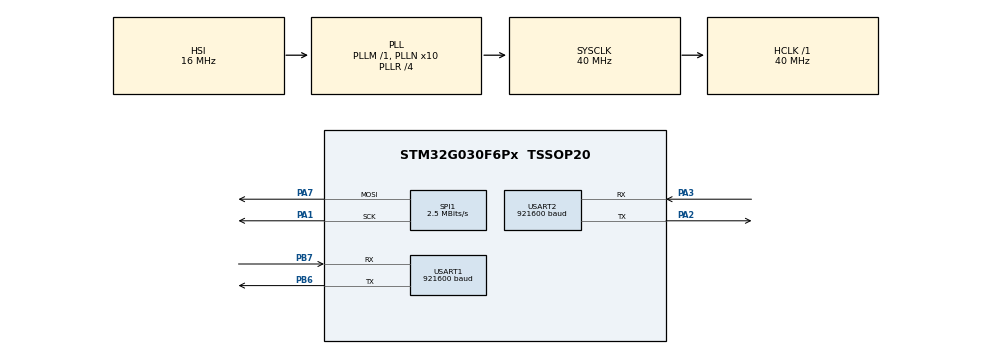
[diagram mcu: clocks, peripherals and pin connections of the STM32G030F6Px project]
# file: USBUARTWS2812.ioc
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Dma.Request0=SPI1_TX
Dma.Request1=USART1_RX
Dma.Request2=USART2_TX
Dma.SPI1_TX.0.Direction=DMA_MEMORY_TO_PERIPH
Dma.SPI1_TX.0.EventEnable=DISABLE
Dma.SPI1_TX.0.Instance=DMA1_Channel1
Dma.SPI1_TX.0.MemDataAlignment=DMA_MDATAALIGN_BYTE
Dma.SPI1_TX.0.MemInc=DMA_MINC_ENABLE
Dma.SPI1_TX.0.Mode=DMA_NORMAL
Dma.SPI1_TX.0.PeriphDataAlignment=DMA_PDATAALIGN_BYTE
Dma.SPI1_TX.0.PeriphInc=DMA_PINC_DISABLE
Dma.SPI1_TX.0.Polarity=HAL_DMAMUX_REQ_GEN_RISING
Dma.SPI1_TX.0.Priority=DMA_PRIORITY_LOW
Dma.SPI1_TX.0.RequestNumber=1
Dma.SPI1_TX.0.SignalID=NONE
Dma.SPI1_TX.0.SyncEnable=DISABLE
Dma.SPI1_TX.0.SyncPolarity=HAL_DMAMUX_SYNC_NO_EVENT
Dma.SPI1_TX.0.SyncRequestNumber=1
Dma.SPI1_TX.0.SyncSignalID=NONE
Dma.USART1_RX.1.Direction=DMA_PERIPH_TO_MEMORY
Dma.USART1_RX.1.EventEnable=DISABLE
Dma.USART1_RX.1.Instance=DMA1_Channel2
Dma.USART1_RX.1.MemDataAlignment=DMA_MDATAALIGN_BYTE
Dma.USART1_RX.1.MemInc=DMA_MINC_ENABLE
Dma.USART1_RX.1.Mode=DMA_NORMAL
Dma.USART1_RX.1.PeriphDataAlignment=DMA_PDATAALIGN_BYTE
Dma.USART1_RX.1.PeriphInc=DMA_PINC_DISABLE
Dma.USART1_RX.1.Polarity=HAL_DMAMUX_REQ_GEN_RISING
Dma.USART1_RX.1.Priority=DMA_PRIORITY_LOW
Dma.USART1_RX.1.RequestNumber=1
Dma.USART1_RX.1.SignalID=NONE
Dma.USART1_RX.1.SyncEnable=DISABLE
Dma.USART1_RX.1.SyncPolarity=HAL_DMAMUX_SYNC_NO_EVENT
Dma.USART1_RX.1.SyncRequestNumber=1
Dma.USART1_RX.1.SyncSignalID=NONE
Dma.USART2_TX.2.Direction=DMA_MEMORY_TO_PERIPH
Dma.USART2_TX.2.EventEnable=DISABLE
Dma.USART2_TX.2.Instance=DMA1_Channel3
Dma.USART2_TX.2.MemDataAlignment=DMA_MDATAALIGN_BYTE
Dma.USART2_TX.2.MemInc=DMA_MINC_ENABLE
Dma.USART2_TX.2.Mode=DMA_NORMAL
Dma.USART2_TX.2.PeriphDataAlignment=DMA_PDATAALIGN_BYTE
Dma.USART2_TX.2.PeriphInc=DMA_PINC_DISABLE
Dma.USART2_TX.2.Polarity=HAL_DMAMUX_REQ_GEN_RISING
Dma.USART2_TX.2.Priority=DMA_PRIORITY_LOW
Dma.USART2_TX.2.RequestNumber=1
Dma.USART2_TX.2.SignalID=NONE
Dma.USART2_TX.2.SyncEnable=DISABLE
Dma.USART2_TX.2.SyncPolarity=HAL_DMAMUX_SYNC_NO_EVENT
Dma.USART2_TX.2.SyncRequestNumber=1
Dma.USART2_TX.2.SyncSignalID=NONE
Mcu.Family=STM32G0
Mcu.Name=STM32G030F6Px
Mcu.Package=TSSOP20
NVIC.DMA1_Channel1_IRQn=true\:0\:0\:false\:false\:true\:false\:true\:true
NVIC.DMA1_Channel2_3_IRQn=true\:0\:0\:false\:false\:true\:false\:true\:true
NVIC.TIM3_IRQn=true\:0\:0\:false\:false\:true\:true\:true\:true
NVIC.USART1_IRQn=true\:0\:0\:false\:false\:true\:true\:true\:true
NVIC.USART2_IRQn=true\:0\:0\:false\:false\:true\:true\:true\:true
PA1.Mode=TX_Only_Simplex_Unidirect_Master
PA1.Signal=SPI1_SCK
PA13.Mode=Serial_Wire
PA13.Signal=SYS_SWDIO
PA14-BOOT0.Mode=Serial_Wire
PA14-BOOT0.Signal=SYS_SWCLK
PA14-BOOT0__PA15.StandardMode=true
PA2.Mode=Asynchronous
PA2.Signal=USART2_TX
PA3.Mode=Asynchronous
PA3.Signal=USART2_RX
PA7.GPIO_Speed=GPIO_SPEED_FREQ_VERY_HIGH
PA7.Mode=TX_Only_Simplex_Unidirect_Master
PA7.Signal=SPI1_MOSI
PB0__PB1__PB2__PA8.StandardMode=true
PB3__PB4__PB5__PB6.StandardMode=true
PB6.Mode=Asynchronous
PB6.Signal=USART1_TX
PB7.Mode=Asynchronous
PB7.Signal=USART1_RX
PB7__PB8.StandardMode=true
PC14-OSC32_IN\ (PC14)__PB9.StandardMode=true
ProjectManager.HeapSize=0x200
ProjectManager.StackSize=0x400
ProjectManager.TargetToolchain=Makefile
RCC.ADCFreq_Value=40000000
RCC.AHBFreq_Value=40000000
RCC.CortexFreq_Value=40000000
RCC.EXTERNAL_CLOCK_VALUE=12288000
RCC.HCLKFreq_Value=40000000
RCC.HSE_VALUE=8000000
RCC.HSI_VALUE=16000000
RCC.LSE_VALUE=32768
RCC.PLLN=10
RCC.PLLR=RCC_PLLR_DIV4
RCC.SYSCLKFreq_VALUE=40000000
RCC.SYSCLKSource=RCC_SYSCLKSOURCE_PLLCLK
RCC.VCOOutputFreq_Value=160000000
SPI1.BaudRatePrescaler=SPI_BAUDRATEPRESCALER_16
SPI1.CalculateBaudRate=2.5 MBits/s
SPI1.Direction=SPI_DIRECTION_2LINES
SPI1.Mode=SPI_MODE_MASTER
SPI1.NSSPMode=SPI_NSS_PULSE_DISABLE
SPI1.VirtualType=VM_MASTER
TIM3.Period=999
TIM3.Prescaler=39
USART1.BaudRate=921600
USART1.VirtualMode-Asynchronous=VM_ASYNC
USART2.BaudRate=921600
USART2.VirtualMode-Asynchronous=VM_ASYNC
VP_TIM3_VS_ClockSourceINT.Mode=Internal
board=custom

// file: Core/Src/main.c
/* USER CODE BEGIN Header */
/**
  ******************************************************************************
  * @file           : main.c
  * @brief          : Main program body
  ******************************************************************************
  * @attention
  *
  * Copyright (c) 2026 STMicroelectronics.
  * All rights reserved.
  *
  * This software is licensed under terms that can be found in the LICENSE file
  * in the root directory of this software component.
  * If no LICENSE file comes with this software, it is provided AS-IS.
  *
  ******************************************************************************
  */
/* USER CODE END Header */
#include "main.h"
#include "dma.h"
#include "spi.h"
#include "tim.h"
#include "usart.h"
#include "gpio.h"

/* USER CODE BEGIN Includes */
#include <application.h>
/* USER CODE END Includes */

void SystemClock_Config(void);

int main(void)
{

  /* MCU Configuration--------------------------------------------------------*/

  /* Reset of all peripherals, Initializes the Flash interface and the Systick. */
  HAL_Init();

  /* Configure the system clock */
  SystemClock_Config();

  /* Initialize all configured peripherals */
  MX_GPIO_Init();
  MX_DMA_Init();
  MX_SPI1_Init();
  MX_USART1_UART_Init();
  MX_USART2_UART_Init();
  MX_TIM3_Init();
  /* USER CODE BEGIN 2 */
  ws2812_pure(128, 0, 128);
  ws2812_refresh();
  init();
  // start dma receive
  HAL_UARTEx_ReceiveToIdle_DMA(&huart1, rx_buffer, sizeof(rx_buffer));
  // start the interrupt;
  HAL_TIM_Base_Start_IT(&htim3);
  /* USER CODE END 2 */

  /* Infinite loop */
  while (1)
  {

  }
}

void SystemClock_Config(void)
{
  RCC_OscInitTypeDef RCC_OscInitStruct = {0};
  RCC_ClkInitTypeDef RCC_ClkInitStruct = {0};

  /** Configure the main internal regulator output voltage
  */
  HAL_PWREx_ControlVoltageScaling(PWR_REGULATOR_VOLTAGE_SCALE1);

  /** Initializes the RCC Oscillators according to the specified parameters
  * in the RCC_OscInitTypeDef structure.
  */
  RCC_OscInitStruct.OscillatorType = RCC_OSCILLATORTYPE_HSI;
  RCC_OscInitStruct.HSIState = RCC_HSI_ON;
  RCC_OscInitStruct.HSIDiv = RCC_HSI_DIV1;
  RCC_OscInitStruct.HSICalibrationValue = RCC_HSICALIBRATION_DEFAULT;
  RCC_OscInitStruct.PLL.PLLState = RCC_PLL_ON;
  RCC_OscInitStruct.PLL.PLLSource = RCC_PLLSOURCE_HSI;
  RCC_OscInitStruct.PLL.PLLM = RCC_PLLM_DIV1;
  RCC_OscInitStruct.PLL.PLLN = 10;
  RCC_OscInitStruct.PLL.PLLP = RCC_PLLP_DIV2;
  RCC_OscInitStruct.PLL.PLLR = RCC_PLLR_DIV4;
  if (HAL_RCC_OscConfig(&RCC_OscInitStruct) != HAL_OK)
  {
    Error_Handler();
  }

  /** Initializes the CPU, AHB and APB buses clocks
  */
  RCC_ClkInitStruct.ClockType = RCC_CLOCKTYPE_HCLK|RCC_CLOCKTYPE_SYSCLK
                              |RCC_CLOCKTYPE_PCLK1;
  RCC_ClkInitStruct.SYSCLKSource = RCC_SYSCLKSOURCE_PLLCLK;
  RCC_ClkInitStruct.AHBCLKDivider = RCC_SYSCLK_DIV1;
  RCC_ClkInitStruct.APB1CLKDivider = RCC_HCLK_DIV1;

  if (HAL_RCC_ClockConfig(&RCC_ClkInitStruct, FLASH_LATENCY_1) != HAL_OK)
  {
    Error_Handler();
  }
}

void Error_Handler(void)
{
  __disable_irq();
  while (1)
  {
  }
}
